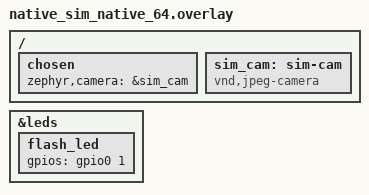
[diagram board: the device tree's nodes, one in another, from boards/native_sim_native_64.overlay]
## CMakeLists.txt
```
# SPDX-License-Identifier: Apache-2.0

cmake_minimum_required(VERSION 3.20.0)

# WiFi, PSRAM, coredump and hawkBit: every ESP32 board, none of it on native_sim
if(NOT BOARD MATCHES "^native_sim")
  list(APPEND EXTRA_CONF_FILE ${CMAKE_CURRENT_LIST_DIR}/esp32.conf)
endif()

find_package(Zephyr REQUIRED HINTS $ENV{ZEPHYR_BASE})

project(prusa_cam)

include(${CMAKE_CURRENT_LIST_DIR}/../common/http_util/http_util.cmake)
include(${CMAKE_CURRENT_LIST_DIR}/../common/prusa_camera/prusa_camera.cmake)
include(${CMAKE_CURRENT_LIST_DIR}/../common/build_id/build_id.cmake)
include(${CMAKE_CURRENT_LIST_DIR}/../common/watchdog/watchdog.cmake)
include(${CMAKE_CURRENT_LIST_DIR}/../common/img_confirm/img_confirm.cmake)

target_sources(app PRIVATE
  src/main.c
  src/cfg.c
  src/cam.c
  src/connect.c
  src/stream.c
  src/web.c
)
target_sources_ifdef(CONFIG_WIFI app PRIVATE src/wifi.c)
target_sources_ifdef(CONFIG_PRUSA_CAM_ESPHOME app PRIVATE src/ha.c)
target_include_directories(app PRIVATE src)

set(gen_dir ${ZEPHYR_BINARY_DIR}/include/generated)
generate_inc_file_for_target(app src/index.html ${gen_dir}/index.html.gz.inc --gzip)

if(CONFIG_DT_HAS_VND_JPEG_CAMERA_ENABLED)
  target_sources(app PRIVATE sim/sim_cam.c)
  generate_inc_file_for_target(app sim/frame.jpg ${gen_dir}/sim_frame.jpg.inc)
endif()

zephyr_linker_sources(SECTIONS sections-rom.ld)
zephyr_linker_section(NAME http_resource_desc_prusa_http
  KVMA RAM_REGION GROUP RODATA_REGION
)
```

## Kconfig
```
# SPDX-License-Identifier: Apache-2.0

mainmenu "prusa_cam"

menu "prusa_cam"

config PRUSA_CAM_CONNECT_STACK_SIZE
	int "Uploader thread stack size"
	default 6144
	help
	  The TLS handshake runs on this stack.

config PRUSA_CAM_STREAM_STACK_SIZE
	int "MJPEG stream thread stack size"
	default 2048

config PRUSA_CAM_MANUFACTURER
	string "Camera manufacturer reported to Prusa Connect"
	default "DFRobot" if BOARD_DFROBOT_ESP32S3_AI_CAM
	default "AI-Thinker"

config PRUSA_CAM_MODEL
	string "Camera model reported to Prusa Connect"
	default "DFR1154" if BOARD_DFROBOT_ESP32S3_AI_CAM
	default "ESP32-CAM"

# native_sim binds host ports: below 1024 needs root, and protective_stop
# has 8080 when twister runs both at once.
config PRUSA_CAM_HTTP_PORT
	int "Config page and API port"
	default 8280 if BOARD_NATIVE_SIM
	default 80

config PRUSA_CAM_STREAM_PORT
	int "MJPEG stream port"
	default 8281 if BOARD_NATIVE_SIM
	default 81
	help
	  The config page links to port 81.

config PRUSA_CAM_ESPHOME
	bool "Home Assistant (ESPHome native API)"
	default y
	select ESPHOME_API
	select ESPHOME_API_NOISE
	help
	  Show the camera in Home Assistant as an ESPHome device: the
	  picture, upload status, uploads, WiFi signal, the flash LED setting
	  and an upload button. Noise encrypted; set the key with `prusa ha_key` or the
	  config page. Until a key is set every client is refused.

config ZVFS_OPEN_ADD_SIZE_PRUSA_CAM_ESPHOME
	int
	default 2 if PRUSA_CAM_ESPHOME
	default 0
	help
	  The API's listening socket and its one client.

endmenu

rsource "../common/prusa_camera/Kconfig"
rsource "../common/build_id/Kconfig"
rsource "../common/watchdog/Kconfig"
rsource "../common/img_confirm/Kconfig"

source "Kconfig.zephyr"
```

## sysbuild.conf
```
# MCUboot, so hawkBit has a slot to download into.
SB_CONFIG_BOOTLOADER_MCUBOOT=y
# Espressif sysbuild defaults to overwrite-only, which cannot revert a bad
# image; swap-using-move reverts a trial image that is never confirmed.
SB_CONFIG_MCUBOOT_MODE_SWAP_USING_MOVE=y
```

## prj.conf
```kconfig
CONFIG_LOG=y
CONFIG_SHELL=y
CONFIG_MAIN_STACK_SIZE=4096
# 4096 for the hawkBit autohandler, which runs its HTTP buffers on this stack.
CONFIG_SYSTEM_WORKQUEUE_STACK_SIZE=4096

# Config + WiFi credentials in ZMS on the storage partition
CONFIG_FLASH=y
CONFIG_FLASH_MAP=y
CONFIG_ZMS=y
CONFIG_SETTINGS=y
CONFIG_SETTINGS_ZMS=y
CONFIG_HWINFO=y

# Camera: JPEG frames (OV2640 over I2S0 camera mode on the ESP32-CAM)
CONFIG_VIDEO=y
CONFIG_VIDEO_BUFFER_POOL_NUM_MAX=2
CONFIG_VIDEO_BUFFER_POOL_ALIGN=4
CONFIG_LED=y

# Networking; the WiFi station is in the board configuration
CONFIG_NETWORKING=y
CONFIG_NET_IPV4=y
CONFIG_NET_IPV6=n
CONFIG_NET_SOCKETS=y
CONFIG_NET_HOSTNAME_ENABLE=y
CONFIG_NET_HOSTNAME="prusa-zcam"

# HTTPS to Prusa Connect (the camera service)
CONFIG_PRUSA_CAMERA=y
CONFIG_HTTP_CLIENT=y
CONFIG_NET_SOCKETS_SOCKOPT_TLS=y
CONFIG_TLS_CREDENTIALS=y
CONFIG_MBEDTLS=y
CONFIG_MBEDTLS_ENABLE_HEAP=y
CONFIG_MBEDTLS_HEAP_SIZE=60000
# Server records can be 16 KiB (no max_fragment_length guarantee); requests are small chunks.
CONFIG_MBEDTLS_SSL_IN_CONTENT_LEN=16384
CONFIG_MBEDTLS_SSL_OUT_CONTENT_LEN=4096
CONFIG_MBEDTLS_SSL_PROTO_TLS1_2=y
CONFIG_MBEDTLS_X509_CRT_PARSE_C=y
CONFIG_MBEDTLS_SSL_SERVER_NAME_INDICATION=y
CONFIG_MBEDTLS_SSL_EXTENDED_MASTER_SECRET=y
# Let's Encrypt chains are RSA (R1x) or ECDSA (E-series); accept both.
CONFIG_MBEDTLS_KEY_EXCHANGE_ECDHE_RSA_ENABLED=y
CONFIG_MBEDTLS_KEY_EXCHANGE_ECDHE_ECDSA_ENABLED=y
CONFIG_PSA_WANT_ALG_ECDH=y
CONFIG_PSA_WANT_ALG_ECDSA=y
CONFIG_PSA_WANT_ALG_RSA_PKCS1V15_SIGN=y
CONFIG_PSA_WANT_ALG_RSA_PSS=y
CONFIG_PSA_WANT_ALG_SHA_256=y
CONFIG_PSA_WANT_ALG_SHA_384=y
CONFIG_PSA_WANT_ALG_GCM=y
CONFIG_PSA_WANT_ALG_HMAC=y
CONFIG_PSA_WANT_ALG_TLS12_PRF=y
CONFIG_PSA_WANT_KEY_TYPE_AES=y
CONFIG_PSA_WANT_KEY_TYPE_ECC_PUBLIC_KEY=y
CONFIG_PSA_WANT_KEY_TYPE_ECC_KEY_PAIR_IMPORT=y
CONFIG_PSA_WANT_KEY_TYPE_ECC_KEY_PAIR_EXPORT=y
CONFIG_PSA_WANT_KEY_TYPE_ECC_KEY_PAIR_GENERATE=y
CONFIG_PSA_WANT_KEY_TYPE_RSA_PUBLIC_KEY=y
CONFIG_PSA_WANT_KEY_TYPE_RSA_KEY_PAIR_IMPORT=y
CONFIG_PSA_WANT_ECC_SECP_R1_256=y
CONFIG_PSA_WANT_ECC_SECP_R1_384=y

# Home Assistant (PRUSA_CAM_ESPHOME): one client is enough for Home Assistant.
CONFIG_ESPHOME_API_MAX_CLIENTS=1
CONFIG_ESPHOME_API_FRIENDLY_NAME="Prusa camera"

# Config page / API
CONFIG_HTTP_SERVER=y
CONFIG_HTTP_PARSER=y
CONFIG_HTTP_SERVER_MAX_CLIENTS=2
CONFIG_HTTP_SERVER_STACK_SIZE=3072
CONFIG_HTTP_SERVER_VERSION_2=n
CONFIG_HTTP_SERVER_CAPTURE_HEADERS=y
# "Basic " + base64("admin:" + 32-char password) = 58; the default 32 cuts it
CONFIG_HTTP_SERVER_MAX_HEADER_LEN=58
CONFIG_JSON_LIBRARY=y
CONFIG_BASE64=y

# Stall detection. Also the deadline img_confirm reverts a trial image with.
CONFIG_APP_WATCHDOG=y
```

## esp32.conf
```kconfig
# Frames in PSRAM
CONFIG_VIDEO_BUFFER_USE_SHARED_MULTI_HEAP=y
CONFIG_VIDEO_BUFFER_SMH_ATTRIBUTE=2
CONFIG_ESP_SPIRAM=y
# DRAM is the tight resource on the ESP32 (mbedTLS heap + DMA ring + WiFi):
# put the WiFi adapter heap and net buffers in PSRAM.
CONFIG_ESP_WIFI_HEAP_SPIRAM=y
CONFIG_ESP32_WIFI_NET_ALLOC_SPIRAM=y
# Two UXGA JPEG buffers (2 x 384 KB) plus the WiFi heap.
CONFIG_ESP_SPIRAM_HEAP_SIZE=2097152
CONFIG_LED_PWM=y

# WiFi station
CONFIG_WIFI=y
CONFIG_NET_L2_WIFI_MGMT=y
CONFIG_NET_L2_WIFI_SHELL=y
CONFIG_WIFI_CREDENTIALS=y
CONFIG_WIFI_CREDENTIALS_BACKEND_SETTINGS=y
CONFIG_WIFI_CREDENTIALS_SHELL=y
CONFIG_NET_DHCPV4=y
CONFIG_NET_TCP=y
CONFIG_NET_SHELL=y
CONFIG_DNS_RESOLVER=y
# <hostname>.local, plus an _http._tcp record for the config page
CONFIG_MDNS_RESPONDER=y
CONFIG_DNS_SD=y
# HTTP server (listen + 2 clients), stream (listen + 1), TLS upload, DNS, mDNS,
# Home Assistant API (listen + 1) plus closed connections still in TIME_WAIT:
# with 10, back-to-back requests got RST
CONFIG_NET_MAX_CONTEXTS=18
CONFIG_NET_MAX_CONN=18
# app_wifi starts DHCP itself, or sets the static address instead.
CONFIG_WIFI_STA_AUTO_DHCPV4=n

# The ESP32 linker script puts .mbedtls_heap in PSRAM (ext_ram.bss).
CONFIG_MBEDTLS_HEAP_CUSTOM_SECTION=y

# The task watchdog's hardware fallback is the TIMG watchdog (watchdog0).
CONFIG_TASK_WDT_HW_FALLBACK=y

# Coredump to the 4 KB `coredump` flash partition, read back over the shell with
# `coredump find`, `coredump print` and `coredump erase`. The partition cannot
# hold RAM, so keep the faulting thread's registers and top 2 KB of stack; the
# default limit is unbounded.
CONFIG_DEBUG_COREDUMP=y
CONFIG_DEBUG_COREDUMP_BACKEND_FLASH_PARTITION=y
CONFIG_DEBUG_COREDUMP_SHELL=y
CONFIG_DEBUG_COREDUMP_MEMORY_DUMP_MIN=y
CONFIG_DEBUG_COREDUMP_THREAD_STACK_TOP_LIMIT_FOR_CURRENT=2048

# hawkBit OTA into MCUboot slot1. Build with --sysbuild (sysbuild.conf).
#
# A new image boots on trial and is confirmed once it has an IPv4 address and
# a frame from the camera (applications/common/img_confirm); otherwise the task
# watchdog resets it and MCUboot reverts. The autohandler only runs on a
# confirmed image, which is why HAWKBIT_CONFIRM_IMG_ON_INIT is off.
#
# Server, port and DDI token are set at runtime (`hawkbit set addr|port|
# ddi_token`) and kept in settings; the server may be a host name.
CONFIG_REBOOT=y
CONFIG_STREAM_FLASH=y
CONFIG_IMG_MANAGER=y
CONFIG_IMG_ERASE_PROGRESSIVELY=y
CONFIG_HAWKBIT=y
CONFIG_HAWKBIT_CONFIRM_IMG_ON_INIT=n
CONFIG_HAWKBIT_SET_SETTINGS_RUNTIME=y
CONFIG_HAWKBIT_USE_DOMAIN_NAME=y
CONFIG_HAWKBIT_SHELL=y
CONFIG_HAWKBIT_DDI_TARGET_SECURITY=y
CONFIG_HAWKBIT_HWINFO_DEVICE_ID=y
CONFIG_SMF=y
CONFIG_SMF_ANCESTOR_SUPPORT=y
# Resume an interrupted download (HTTP Range); progress saved every 5 %.
CONFIG_HAWKBIT_SAVE_PROGRESS=y
CONFIG_HAWKBIT_SAVE_PROGRESS_INTERVAL=5
CONFIG_STREAM_FLASH_PROGRESS=y
```

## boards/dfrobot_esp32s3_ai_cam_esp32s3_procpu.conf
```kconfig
# The DVP DMA writes a frame straight into its buffer: a UXGA JPEG buffer
# (1600 x 1200 / 5 B) takes 96 descriptors of 4032 B.
CONFIG_DMA_ESP32_MAX_DESCRIPTOR_NUM=100
# The GDMA stalls writing to PSRAM at less than 64-byte alignment.
CONFIG_VIDEO_BUFFER_POOL_ALIGN=64
```

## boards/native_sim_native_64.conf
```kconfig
# Host-backed BSD sockets: the HTTP server, the MJPEG stream and the uploads
# use the host's loopback directly, with no TAP interface and no root.
CONFIG_NET_SOCKETS_OFFLOAD=y
CONFIG_NET_NATIVE_OFFLOADED_SOCKETS=y
CONFIG_NET_DRIVERS=y
CONFIG_NET_L2_ETHERNET=n
CONFIG_NET_NATIVE=n

# ZMS on flash_simulator, persisted to a host file.
CONFIG_FLASH_SIMULATOR=y
CONFIG_FLASH_SIMULATOR_DOUBLE_WRITES=y

CONFIG_GPIO=y
CONFIG_PSA_CRYPTO=y
CONFIG_NET_MGMT=y
CONFIG_NET_MGMT_EVENT=y
CONFIG_NET_IF_UNICAST_IPV4_ADDR_COUNT=4
CONFIG_UART_NATIVE_PTY_0_ON_STDINOUT=y
# Sockets come from the fd table; NET_MAX_CONTEXTS sizes it on hardware.
CONFIG_ZVFS_OPEN_MAX=18
```

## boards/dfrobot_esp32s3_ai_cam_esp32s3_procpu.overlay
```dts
/* cam.c drives the "flash" through this label: the IR LEDs on this board. */
/ {
	pwmleds {
		flash_led: ir_led {};
	};
};
```

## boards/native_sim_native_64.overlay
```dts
/*
 * Copyright (c) 2026 Richard Osterloh <richard.osterloh@gmail.com>
 * SPDX-License-Identifier: Apache-2.0
 *
 * A canned-JPEG camera (sim/sim_cam.c) and a GPIO flash LED, so the whole app
 * runs on the host.
 */

/ {
	chosen {
		zephyr,camera = &sim_cam;
	};

	sim_cam: sim-cam {
		compatible = "vnd,jpeg-camera";
	};
};

&leds {
	flash_led: flash_led {
		gpios = <&gpio0 1 GPIO_ACTIVE_HIGH>;
	};
};
```

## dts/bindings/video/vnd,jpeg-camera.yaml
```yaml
# Copyright (c) 2026 Richard Osterloh
# SPDX-License-Identifier: Apache-2.0

description: |
  Stand-in JPEG camera for native_sim builds of prusa_cam: every frame is the
  same small JPEG (sim/frame.jpg).

compatible: "vnd,jpeg-camera"

include: base.yaml
```

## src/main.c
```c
/*
 * Copyright (c) 2026 Richard Osterloh <richard.osterloh@gmail.com>
 * SPDX-License-Identifier: Apache-2.0
 *
 * Prusa Connect camera: periodic JPEG snapshots from an OV2640 or OV3660 uploaded to
 * Prusa Connect, configured from the shell or a small web page.
 */

#include <stdlib.h>
#include <string.h>

#include <zephyr/dfu/mcuboot.h>
#include <zephyr/kernel.h>
#include <zephyr/logging/log.h>
#include <zephyr/mgmt/hawkbit/autohandler.h>
#include <zephyr/mgmt/hawkbit/hawkbit.h>
#include <zephyr/net/net_mgmt.h>
#include <zephyr/net/net_event.h>
#include <zephyr/shell/shell.h>

#include "app_img_confirm.h"
#include "app_watchdog.h"
#include "app_wifi.h"
#include "cam.h"
#include "cfg.h"
#include "connect.h"
#include "ha.h"
#include "http_util.h"
#include "prusa_camera.h"

LOG_MODULE_REGISTER(main, LOG_LEVEL_INF);

int web_init(void);

void cfg_changed(void)
{
	struct cfg c;

	cfg_get(&c);
	cam_apply(&c);
	connect_kick();
}

#define IP4(a) (a) >> 24, ((a) >> 16) & 0xFF, ((a) >> 8) & 0xFF, (a) & 0xFF

/* "dhcp" or "0" clears; otherwise A.B.C.D. */
static bool parse_ip(const char *val, uint32_t *out)
{
	if (strcmp(val, "dhcp") == 0 || strcmp(val, "0") == 0) {
		*out = 0;
		return true;
	}
	return http_parse_ipv4(val, out) == 0;
}

static int cmd_show(const struct shell *sh, size_t argc, char **argv)
{
	struct cfg c;
	struct connect_status st;

	cfg_get(&c);
	connect_get_status(&st);
	shell_print(sh, "name:        %s", c.name);
	shell_print(sh, "token:       %s", c.token[0] ? "set" : "not set");
	shell_print(sh, "password:    %s", c.password[0] ? "set" : "not set");
	shell_print(sh, "fingerprint: %s", cfg_fingerprint());
	shell_print(sh, "interval:    %u s", c.interval_s);
	shell_print(sh, "resolution:  %s", cfg_resolutions[c.resolution].name);
	shell_print(sh, "quality:     %u", c.quality);
	shell_print(sh, "hflip/vflip: %d/%d, flash: %d", c.hflip, c.vflip, c.flash);
	shell_print(sh, "rotation:    %u", c.rotation * 90);
	shell_print(sh, "brightness/contrast/saturation: %d/%d/%d", c.brightness, c.contrast,
		    c.saturation);
	shell_print(sh, "auto exposure/wb/gain: %d/%d/%d", c.auto_exposure, c.auto_wb, c.auto_gain);
	if (c.ip == 0) {
		shell_print(sh, "address:     DHCP");
	} else {
		shell_print(sh,
			    "address:     %u.%u.%u.%u/%u.%u.%u.%u gw %u.%u.%u.%u dns %u.%u.%u.%u",
			    IP4(c.ip), IP4(c.netmask), IP4(c.gateway), IP4(c.dns));
	}
	shell_print(sh, "uploads:     %u, last result %d (%s)%s", st.uploads, st.last_result,
		    st.last_ms ? prusa_camera_describe(st.last_result) : "none yet",
		    st.stopped ? ", stopped until the config changes" : "");
	memset(&c, 0, sizeof(c));
	return 0;
}

static int cmd_set(const struct shell *sh, size_t argc, char **argv)
{
	const char *key = argv[1];
	const char *val = argv[2];
	struct cfg c;
	int ret;

	cfg_get(&c);
	if (strcmp(key, "name") == 0 && strlen(val) <= CFG_NAME_MAX) {
		strcpy(c.name, val);
	} else if (strcmp(key, "token") == 0 && strlen(val) <= CFG_TOKEN_MAX) {
		strcpy(c.token, val);
	} else if (strcmp(key, "password") == 0 && strlen(val) <= CFG_PASSWORD_MAX) {
		strcpy(c.password, val);
	} else if (strcmp(key, "interval") == 0) {
		c.interval_s = CLAMP(strtol(val, NULL, 10), 0, UINT16_MAX);
	} else if (strcmp(key, "resolution") == 0 && cfg_resolution_find(val) >= 0) {
		c.resolution = cfg_resolution_find(val);
	} else if (strcmp(key, "quality") == 0) {
		c.quality = CLAMP(strtol(val, NULL, 10), 0, UINT8_MAX);
	} else if (strcmp(key, "hflip") == 0) {
		c.hflip = strtol(val, NULL, 10) != 0;
	} else if (strcmp(key, "vflip") == 0) {
		c.vflip = strtol(val, NULL, 10) != 0;
	} else if (strcmp(key, "flash") == 0) {
		c.flash = strtol(val, NULL, 10) != 0;
	} else if (strcmp(key, "rotation") == 0 && strtol(val, NULL, 10) % 90 == 0) {
		c.rotation = CLAMP(strtol(val, NULL, 10) / 90, 0, UINT8_MAX);
	} else if (strcmp(key, "brightness") == 0) {
		c.brightness = CLAMP(strtol(val, NULL, 10), INT8_MIN, INT8_MAX);
	} else if (strcmp(key, "contrast") == 0) {
		c.contrast = CLAMP(strtol(val, NULL, 10), INT8_MIN, INT8_MAX);
	} else if (strcmp(key, "saturation") == 0) {
		c.saturation = CLAMP(strtol(val, NULL, 10), INT8_MIN, INT8_MAX);
	} else if (strcmp(key, "auto_exposure") == 0) {
		c.auto_exposure = strtol(val, NULL, 10) != 0;
	} else if (strcmp(key, "auto_wb") == 0) {
		c.auto_wb = strtol(val, NULL, 10) != 0;
	} else if (strcmp(key, "auto_gain") == 0) {
		c.auto_gain = strtol(val, NULL, 10) != 0;
	} else if ((strcmp(key, "ip") == 0 && parse_ip(val, &c.ip)) ||
		   (strcmp(key, "netmask") == 0 && parse_ip(val, &c.netmask)) ||
		   (strcmp(key, "gateway") == 0 && parse_ip(val, &c.gateway)) ||
		   (strcmp(key, "dns") == 0 && parse_ip(val, &c.dns))) {
		/* parsed in place */
	} else {
		shell_error(sh, "bad key or value");
		return -EINVAL;
	}

	ret = cfg_set(&c);
	memset(&c, 0, sizeof(c));
	if (ret < 0) {
		shell_error(sh, "rejected (%d)", ret);
	}
	return ret;
}

static int cmd_test(const struct shell *sh, size_t argc, char **argv)
{
	connect_test();
	shell_print(sh, "test queued; see `prusa show` in a few seconds");
	return 0;
}

static int cmd_snap(const struct shell *sh, size_t argc, char **argv)
{
	connect_kick();
	shell_print(sh, "upload queued");
	return 0;
}

static int cmd_ha_key(const struct shell *sh, size_t argc, char **argv)
{
	int ret = ha_set_key(argv[1]);

	if (ret < 0) {
		shell_error(sh, "expected base64 of 32 bytes, or save failed (%d)", ret);
	}
	return ret;
}

SHELL_STATIC_SUBCMD_SET_CREATE(
	prusa_cmds,
	SHELL_CMD_ARG(show, NULL, "Show configuration and upload status", cmd_show, 1, 0),
	SHELL_CMD_ARG(
		set, NULL,
		"Set <name|token|password|interval|resolution|quality|hflip|vflip|flash|\n"
		"     rotation|brightness|contrast|saturation|auto_exposure|auto_wb|auto_gain|\n"
		"     ip|netmask|gateway|dns> <value>\n"
		"token: 20 letters/digits; interval: 10 30 60 600\n"
		"resolution: QVGA VGA SVGA XGA SXGA UXGA; rotation: 0 90 180 270\n"
		"brightness/contrast/saturation: -2..2; auto_*: 0 or 1\n"
		"ip: A.B.C.D or dhcp; set netmask and gateway first; applies on reconnect",
		cmd_set, 3, 0),
	SHELL_CMD_ARG(test, NULL, "Check token and fingerprint with the service", cmd_test, 1, 0),
	SHELL_CMD_ARG(snap, NULL, "Upload a snapshot now", cmd_snap, 1, 0),
	SHELL_COND_CMD_ARG(CONFIG_PRUSA_CAM_ESPHOME, ha_key, NULL,
			   "Set the Home Assistant encryption key <base64 of 32 bytes>", cmd_ha_key,
			   2, 0),
	SHELL_SUBCMD_SET_END);
SHELL_CMD_REGISTER(prusa, &prusa_cmds, "Prusa Connect camera", NULL);

/* Only on a confirmed image: the autohandler reboots an unconfirmed one, which
 * would cut the img_confirm deadline short. A confirmed image starts it even
 * with a broken camera, so OTA can fix it.
 */
static void hawkbit_start_fn(struct k_work *work)
{
	static bool started;
	int ret;

	if (!IS_ENABLED(CONFIG_HAWKBIT) || started || !boot_is_img_confirmed()) {
		return;
	}
	ret = hawkbit_init();
	if (ret < 0) {
		LOG_ERR("hawkBit init failed (%d)", ret);
		return;
	}
	started = true;
	hawkbit_autohandler(true);
}

static K_WORK_DEFINE(hawkbit_start, hawkbit_start_fn);

static bool cam_ok;
static struct net_mgmt_event_callback ipv4_cb;

/* Healthy = a frame from the camera and an IPv4 address. */
static void ipv4_added(struct net_mgmt_event_callback *cb, uint64_t event, struct net_if *iface)
{
	if (cam_ok) {
		app_img_confirm();
	}
	k_work_submit(&hawkbit_start);
}

static bool cam_check(void)
{
	const uint8_t *jpeg;
	size_t len;

	if (cam_frame(&jpeg, &len) < 0) {
		return false;
	}
	cam_release();
	return true;
}

int main(void)
{
	int ret;

	app_watchdog_init();
	app_img_confirm_arm();

	ret = cfg_init();
	if (ret < 0) {
		LOG_ERR("Config init failed (%d)", ret);
		return ret;
	}
	LOG_INF("Fingerprint %s", cfg_fingerprint());

	ret = cam_init();
	if (ret < 0) {
		LOG_ERR("Camera init failed (%d)", ret); /* keep going: the shell still works */
	} else {
		cam_ok = cam_check();
	}
	if (!cam_ok) {
		LOG_ERR("No frame from the camera; a trial image will be reverted");
	}

	ret = connect_init();
	if (ret < 0) {
		LOG_ERR("Connect init failed (%d)", ret);
		return ret;
	}

	if (IS_ENABLED(CONFIG_PRUSA_CAM_ESPHOME)) {
		ha_start();
	}

	ret = web_init();
	if (ret < 0) {
		LOG_ERR("HTTP server failed (%d)", ret);
	}

	net_mgmt_init_event_callback(&ipv4_cb, ipv4_added, NET_EVENT_IPV4_ADDR_ADD);
	net_mgmt_add_event_callback(&ipv4_cb);
	k_work_submit(&hawkbit_start);

	return IS_ENABLED(CONFIG_WIFI) ? app_wifi_init() : 0;
}
```

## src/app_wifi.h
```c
/*
 * Copyright (c) 2026 Richard Osterloh <richard.osterloh@gmail.com>
 * SPDX-License-Identifier: Apache-2.0
 */

#ifndef PRUSA_CAM_APP_WIFI_H_
#define PRUSA_CAM_APP_WIFI_H_

int app_wifi_init(void);
void app_wifi_reconnect(void);

#endif /* PRUSA_CAM_APP_WIFI_H_ */
```

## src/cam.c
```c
/*
 * Copyright (c) 2026 Richard Osterloh <richard.osterloh@gmail.com>
 * SPDX-License-Identifier: Apache-2.0
 */

#include <errno.h>

#include <zephyr/device.h>
#include <zephyr/drivers/led.h>
#include <zephyr/drivers/video.h>
#include <zephyr/kernel.h>
#include <zephyr/logging/log.h>
#include <zephyr/video/video.h>

#include "cam.h"

LOG_MODULE_REGISTER(cam, LOG_LEVEL_INF);

#define NBUF          2
#define FRAME_TIMEOUT K_SECONDS(3)
/* Upstream caps the flash LED at 80 % to spare it. */
#define FLASH_PERCENT 80
#define FLASH_SETTLE  K_MSEC(150)

static const struct device *const video = DEVICE_DT_GET(DT_CHOSEN(zephyr_camera));
static const struct led_dt_spec flash_led = LED_DT_SPEC_GET(DT_NODELABEL(flash_led));

static struct video_buffer *bufs[NBUF];
static struct video_buffer *held;
static bool use_flash;
static K_MUTEX_DEFINE(cam_lock);

static int set_ctrl(uint32_t id, int32_t val)
{
	struct video_control ctrl = {.id = id, .val = val};
	int ret = video_set_ctrl(video, &ctrl);

	if (ret < 0 && ret != -ENOTSUP) {
		LOG_WRN("ctrl 0x%x=%d: %d", id, val, ret);
	}
	return ret;
}

static void requeue_all(void)
{
	struct video_buffer *vb;

	while (video_dequeue(video, &vb, K_NO_WAIT) == 0) {
		video_enqueue(video, vb);
	}
}

int cam_apply(const struct cfg *c)
{
	const struct cfg_resolution *r = &cfg_resolutions[c->resolution];
	struct video_format fmt = {
		.type = VIDEO_BUF_TYPE_OUTPUT,
		.pixelformat = VIDEO_PIX_FMT_JPEG,
		.width = r->width,
		.height = r->height,
	};
	struct video_buffer *vb;
	int ret;

	if (!device_is_ready(video)) {
		return -ENODEV;
	}

	k_mutex_lock(&cam_lock, K_FOREVER);

	/* Stopping flushes every buffer to the output queue; drain it so none is queued twice. */
	video_stream_stop(video, VIDEO_BUF_TYPE_OUTPUT);
	while (video_dequeue(video, &vb, K_NO_WAIT) == 0) {
	}

	ret = video_set_format(video, &fmt);
	if (ret < 0) {
		LOG_ERR("%s JPEG not supported (%d)", r->name, ret);
		goto out;
	}

	/* The DVP driver estimates 2 B/px for JPEG; 1/5 B/px holds a frame at the
	 * default quality, and drivers drop a larger one.
	 */
	fmt.size = MIN(fmt.size, (uint32_t)fmt.width * fmt.height / 5);

	for (int i = 0; i < NBUF; i++) {
		if (bufs[i] != NULL && bufs[i]->size < fmt.size) {
			video_buffer_release(bufs[i]);
			bufs[i] = NULL;
		}
		if (bufs[i] == NULL) {
			bufs[i] = video_buffer_aligned_alloc(
				fmt.size, CONFIG_VIDEO_BUFFER_POOL_ALIGN, K_NO_WAIT);
			if (bufs[i] == NULL) {
				LOG_ERR("No memory for a %u B frame", fmt.size);
				ret = -ENOMEM;
				goto out;
			}
		}
		bufs[i]->type = VIDEO_BUF_TYPE_OUTPUT;
		video_enqueue(video, bufs[i]);
	}

	set_ctrl(VIDEO_CID_JPEG_COMPRESSION_QUALITY, c->quality);
	set_ctrl(VIDEO_CID_HFLIP, c->hflip);
	set_ctrl(VIDEO_CID_VFLIP, c->vflip);
	set_ctrl(VIDEO_CID_BRIGHTNESS, c->brightness);
	set_ctrl(VIDEO_CID_CONTRAST, c->contrast);
	set_ctrl(VIDEO_CID_SATURATION, c->saturation);
	/* The OV2640 driver uses these CIDs as on/off switches for its auto loops. */
	set_ctrl(VIDEO_CID_EXPOSURE, c->auto_exposure);
	set_ctrl(VIDEO_CID_WHITE_BALANCE_TEMPERATURE, c->auto_wb);
	set_ctrl(VIDEO_CID_GAIN, c->auto_gain);
	/* Other sensors (OV3660) take the standard auto controls. */
	set_ctrl(VIDEO_CID_EXPOSURE_AUTO,
		 c->auto_exposure ? VIDEO_EXPOSURE_AUTO : VIDEO_EXPOSURE_MANUAL);
	set_ctrl(VIDEO_CID_AUTO_WHITE_BALANCE, c->auto_wb);
	set_ctrl(VIDEO_CID_AUTOGAIN, c->auto_gain);
	use_flash = c->flash;

	ret = video_stream_start(video, VIDEO_BUF_TYPE_OUTPUT);
	if (ret == 0) {
		LOG_INF("Streaming %s JPEG, %u B buffers", r->name, fmt.size);
	}
out:
	k_mutex_unlock(&cam_lock);
	return ret;
}

int cam_init(void)
{
	struct cfg c;

	if (!device_is_ready(video)) {
		LOG_ERR("%s not ready", video->name);
		return -ENODEV;
	}
	if (!led_is_ready_dt(&flash_led)) {
		return -ENODEV;
	}
	cfg_get(&c);
	return cam_apply(&c);
}

static int grab(const uint8_t **jpeg, size_t *len, bool flash)
{
	int ret;

	if (!device_is_ready(video)) {
		return -ENODEV;
	}

	k_mutex_lock(&cam_lock, K_FOREVER);

	if (flash) {
		led_set_brightness_dt(&flash_led, FLASH_PERCENT);
		k_sleep(FLASH_SETTLE);
	}

	/* Frames already queued are stale: hand them back and wait for a new one. */
	requeue_all();
	ret = video_dequeue(video, &held, FRAME_TIMEOUT);

	if (flash) {
		led_off_dt(&flash_led);
	}

	if (ret < 0) {
		LOG_WRN("No frame (%d)", ret);
		k_mutex_unlock(&cam_lock);
		return ret;
	}

	*jpeg = held->buffer;
	*len = held->bytesused;
	return 0;
}

int cam_snapshot(const uint8_t **jpeg, size_t *len)
{
	return grab(jpeg, len, use_flash);
}

int cam_frame(const uint8_t **jpeg, size_t *len)
{
	return grab(jpeg, len, false);
}

void cam_release(void)
{
	video_enqueue(video, held);
	held = NULL;
	k_mutex_unlock(&cam_lock);
}
```

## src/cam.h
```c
/*
 * Copyright (c) 2026 Richard Osterloh <richard.osterloh@gmail.com>
 * SPDX-License-Identifier: Apache-2.0
 */

#ifndef PRUSA_CAM_CAM_H_
#define PRUSA_CAM_CAM_H_

#include <stddef.h>
#include <stdint.h>

#include "cfg.h"

int cam_init(void);

/* Apply resolution, quality and flips; restarts the stream. */
int cam_apply(const struct cfg *c);

/*
 * Take a fresh JPEG. On success the frame stays valid, and the camera
 * locked, until cam_release().
 */
int cam_snapshot(const uint8_t **jpeg, size_t *len);
/* As cam_snapshot(), never with the flash LED: for the MJPEG stream. */
int cam_frame(const uint8_t **jpeg, size_t *len);
void cam_release(void);

#endif /* PRUSA_CAM_CAM_H_ */
```

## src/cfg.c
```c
/*
 * Copyright (c) 2026 Richard Osterloh <richard.osterloh@gmail.com>
 * SPDX-License-Identifier: Apache-2.0
 */

/* strnlen() */
#define _POSIX_C_SOURCE 200809L

#include <errno.h>
#include <string.h>
#include <strings.h>

#include <zephyr/drivers/hwinfo.h>
#include <zephyr/kernel.h>
#include <zephyr/logging/log.h>
#include <zephyr/settings/settings.h>
#include <zephyr/sys/util.h>

#include "cfg.h"
#include "prusa_camera.h"

LOG_MODULE_REGISTER(cfg, LOG_LEVEL_INF);

const struct cfg_resolution cfg_resolutions[] = {
	{"QVGA", 320, 240}, {"VGA", 640, 480},    {"SVGA", 800, 600},
	{"XGA", 1024, 768}, {"SXGA", 1280, 1024}, {"UXGA", 1600, 1200},
};
const uint8_t cfg_resolution_count = ARRAY_SIZE(cfg_resolutions);

static struct cfg cfg = {
	.name = CONFIG_NET_HOSTNAME,
	.interval_s = 30,
	.resolution = 5, /* UXGA: the service suggests 1280x720..1920x1080 */
	.quality = 80,
	.auto_exposure = true,
	.auto_wb = true,
	.auto_gain = true,
};
static K_MUTEX_DEFINE(cfg_lock);
/* The service wants 16..64 characters; the MAC alone is 12 hex digits. */
#define FP_PREFIX "zephyrcam"
#define FP_ID_MAX ((40 - (sizeof(FP_PREFIX) - 1)) / 2)
static char fingerprint[sizeof(FP_PREFIX) + 2 * FP_ID_MAX];

static int cfg_load(const char *key, size_t len, settings_read_cb read_cb, void *cb_arg)
{
	struct cfg tmp = {0};
	ssize_t n;

	if (strcmp(key, "v1") != 0) {
		return 0;
	}
	n = read_cb(cb_arg, &tmp, sizeof(tmp));
	if (n != sizeof(tmp)) {
		LOG_WRN("Stored config has the wrong size, using defaults");
		return 0;
	}
	tmp.token[CFG_TOKEN_MAX] = '\0';
	tmp.password[CFG_PASSWORD_MAX] = '\0';
	tmp.name[CFG_NAME_MAX] = '\0';
	cfg = tmp;
	return 0;
}

SETTINGS_STATIC_HANDLER_DEFINE(prusa, "prusa", NULL, cfg_load, NULL, NULL);

int cfg_init(void)
{
	uint8_t id[FP_ID_MAX];
	ssize_t n = hwinfo_get_device_id(id, sizeof(id));
	int ret;

	if (n <= 0) {
		LOG_ERR("No device id (%d)", (int)n);
		return n < 0 ? (int)n : -EIO;
	}
	strcpy(fingerprint, FP_PREFIX);
	bin2hex(id, n, fingerprint + strlen(FP_PREFIX), sizeof(fingerprint) - strlen(FP_PREFIX));

	ret = settings_subsys_init();
	if (ret < 0) {
		return ret;
	}
	return settings_load_subtree("prusa");
}

void cfg_get(struct cfg *out)
{
	k_mutex_lock(&cfg_lock, K_FOREVER);
	*out = cfg;
	k_mutex_unlock(&cfg_lock);
}

int cfg_set(const struct cfg *in)
{
	struct cfg tmp = *in;
	int ret;

	if (prusa_camera_trigger_from_seconds(tmp.interval_s) < 0 ||
	    (tmp.token[0] != '\0' && !prusa_camera_token_valid(tmp.token)) || tmp.name[0] == '\0' ||
	    strnlen(tmp.name, sizeof(tmp.name)) > CFG_NAME_MAX ||
	    !IN_RANGE(tmp.brightness, -2, 2) || !IN_RANGE(tmp.contrast, -2, 2) ||
	    !IN_RANGE(tmp.saturation, -2, 2) || tmp.resolution >= cfg_resolution_count ||
	    tmp.quality > 100 || tmp.rotation > 3 ||
	    (tmp.ip != 0 && (tmp.netmask == 0 || tmp.gateway == 0)) ||
	    strnlen(tmp.token, sizeof(tmp.token)) > CFG_TOKEN_MAX ||
	    strnlen(tmp.password, sizeof(tmp.password)) > CFG_PASSWORD_MAX) {
		return -EINVAL;
	}

	k_mutex_lock(&cfg_lock, K_FOREVER);
	ret = settings_save_one("prusa/v1", &tmp, sizeof(tmp));
	if (ret == 0) {
		cfg = tmp;
	}
	k_mutex_unlock(&cfg_lock);

	if (ret == 0) {
		cfg_changed();
	}
	return ret;
}

int cfg_resolution_find(const char *name)
{
	for (int i = 0; i < cfg_resolution_count; i++) {
		if (strcasecmp(name, cfg_resolutions[i].name) == 0) {
			return i;
		}
	}
	return -1;
}

const char *cfg_fingerprint(void)
{
	return fingerprint;
}
```

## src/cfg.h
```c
/*
 * Copyright (c) 2026 Richard Osterloh <richard.osterloh@gmail.com>
 * SPDX-License-Identifier: Apache-2.0
 */

#ifndef PRUSA_CAM_CFG_H_
#define PRUSA_CAM_CFG_H_

#include <stdbool.h>
#include <stdint.h>

#define CFG_TOKEN_MAX    64
#define CFG_PASSWORD_MAX 32
#define CFG_NAME_MAX     32 /* Prusa Connect's limit */

struct cfg_resolution {
	const char *name;
	uint16_t width;
	uint16_t height;
};

struct cfg {
	char token[CFG_TOKEN_MAX + 1];
	char password[CFG_PASSWORD_MAX + 1];
	char name[CFG_NAME_MAX + 1]; /* shown in Prusa Connect */
	uint16_t interval_s;         /* 10, 30, 60 or 600: the service's trigger schemes */
	uint8_t resolution;          /* index into cfg_resolutions[] */
	uint8_t quality;             /* VIDEO_CID_JPEG_COMPRESSION_QUALITY */
	bool hflip;
	bool vflip;
	bool flash;
	uint8_t rotation; /* clockwise, 0..3 = 0/90/180/270 deg, for Connect and Exif */
	/* Host-order IPv4; ip == 0 means DHCP. Applied on the next WiFi connect. */
	uint32_t ip;
	uint32_t netmask;
	uint32_t gateway;
	uint32_t dns; /* 0: use the gateway */
	/* Sensor tuning: levels -2..2, the auto loops on or off */
	int8_t brightness;
	int8_t contrast;
	int8_t saturation;
	bool auto_exposure;
	bool auto_wb;
	bool auto_gain;
};

extern const struct cfg_resolution cfg_resolutions[];
extern const uint8_t cfg_resolution_count;

/* Load from settings (defaults for anything unset). */
int cfg_init(void);

/* Snapshot of the current configuration. */
void cfg_get(struct cfg *out);

/* Validate and persist; -EINVAL leaves the stored config untouched. */
int cfg_set(const struct cfg *in);

/* Index of a resolution by name, or -1. */
int cfg_resolution_find(const char *name);

/* Stable per-device id that Prusa Connect keys the camera on. */
const char *cfg_fingerprint(void);

/* Called after cfg_set() changes anything. */
void cfg_changed(void);

#endif /* PRUSA_CAM_CFG_H_ */
```

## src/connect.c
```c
/*
 * Copyright (c) 2026 Richard Osterloh <richard.osterloh@gmail.com>
 * SPDX-License-Identifier: Apache-2.0
 *
 * Prusa camera service API v1 (https://camera-service.prusa3d.com/docs/):
 * PUT /v1/camera-info (JSON) once and after each config change, then
 * PUT /v1/snapshot (JPEG, at most 1 MB and 6 a minute), each with Token,
 * Fingerprint and User-Agent headers, over HTTPS.
 */

#include <string.h>

#include <zephyr/kernel.h>
#include <zephyr/logging/log.h>
#include <zephyr/net/net_if.h>
#include <zephyr/net/net_mgmt.h>
#include <zephyr/net/wifi_mgmt.h>
#include <zephyr/sys/atomic.h>

#include <zephyr/app_version.h>

#include "cam.h"
#include "cfg.h"
#include "connect.h"
#include "prusa_camera.h"

LOG_MODULE_REGISTER(connect, LOG_LEVEL_INF);

#define BACKOFF_MAX_S 600

enum {
	INFO_STALE,
	TEST_REQUESTED
};

static K_SEM_DEFINE(kick, 0, 1);
static K_MUTEX_DEFINE(status_lock);
static struct connect_status status;
static atomic_t flags = ATOMIC_INIT(BIT(INFO_STALE));
static struct net_mgmt_event_callback addr_cb;

/* network_info for camera-info, filled from the WiFi station interface. */
static struct {
	char mac[sizeof("00:00:00:00:00:00")];
	char ipv4[NET_IPV4_ADDR_LEN];
	char ssid[WIFI_SSID_MAX_LEN + 1];
} net;

static void net_info_update(void)
{
	struct net_if *iface = net_if_get_wifi_sta();
	struct wifi_iface_status st = {0};
	struct net_linkaddr *ll;
	struct net_in_addr *a;

	memset(&net, 0, sizeof(net));
	if (!IS_ENABLED(CONFIG_WIFI) || iface == NULL) {
		return;
	}
	ll = net_if_get_link_addr(iface);
	if (ll != NULL && ll->len == 6) {
		snprintk(net.mac, sizeof(net.mac), "%02x:%02x:%02x:%02x:%02x:%02x", ll->addr[0],
			 ll->addr[1], ll->addr[2], ll->addr[3], ll->addr[4], ll->addr[5]);
	}
	a = net_if_ipv4_get_global_addr(iface, NET_ADDR_PREFERRED);
	if (a != NULL) {
		net_addr_ntop(NET_AF_INET, a, net.ipv4, sizeof(net.ipv4));
	}
	if (net_mgmt(NET_REQUEST_WIFI_IFACE_STATUS, iface, &st, sizeof(st)) == 0 &&
	    st.state >= WIFI_STATE_ASSOCIATED) {
		memcpy(net.ssid, st.ssid, MIN(st.ssid_len, WIFI_SSID_MAX_LEN));
	}
}

/*
 * A new address goes into camera-info, so Connect shows where the camera is.
 * Try now too: after an outage the backoff may have grown to 10 minutes.
 */
static void addr_event(struct net_mgmt_event_callback *cb, uint64_t event, struct net_if *iface)
{
	atomic_set_bit(&flags, INFO_STALE);
	k_sem_give(&kick);
}

static int send_info(const struct prusa_camera_auth *auth, const struct cfg *c)
{
	net_info_update();

	const struct prusa_camera_info info = {
		.name = c->name,
		.trigger = prusa_camera_trigger_from_seconds(c->interval_s),
		.rotation = c->rotation * 90,
		.width = cfg_resolutions[c->resolution].width,
		.height = cfg_resolutions[c->resolution].height,
		.wifi_mac = net.mac,
		.wifi_ipv4 = net.ipv4,
		.wifi_ssid = net.ssid,
		.type = "ESP32",
		.firmware_version = APP_VERSION_STRING,
		.hardware_version = CONFIG_PRUSA_CAM_MANUFACTURER " " CONFIG_PRUSA_CAM_MODEL,
		.manufacturer = CONFIG_PRUSA_CAM_MANUFACTURER,
		.model = CONFIG_PRUSA_CAM_MODEL,
	};

	return prusa_camera_put_info(auth, &info);
}

static int send_snapshot(const struct prusa_camera_auth *auth)
{
	const uint8_t *jpeg;
	size_t len;
	int ret = cam_snapshot(&jpeg, &len);

	if (ret < 0) {
		return ret;
	}
	ret = prusa_camera_put_snapshot(auth, jpeg, len);
	cam_release();
	LOG_INF("Snapshot %u B -> %d", len, ret);
	return ret;
}

static void record(int result, bool uploaded, bool stopped)
{
	k_mutex_lock(&status_lock, K_FOREVER);
	status.last_ms = k_uptime_get();
	status.last_result = result;
	status.uploads += uploaded;
	status.stopped = stopped;
	k_mutex_unlock(&status_lock);
}

/*
 * One step of the upload loop: a requested connection test, camera-info when
 * it is stale, else a snapshot. Returns what the service said to do next.
 */
static enum prusa_camera_next step(const struct prusa_camera_auth *auth, const struct cfg *c,
				   bool *stopped)
{
	static const char *const what[] = {"test", "camera-info", "snapshot"};
	enum {
		TEST,
		INFO,
		SNAPSHOT
	} kind;
	enum prusa_camera_next next;
	int ret;

	if (atomic_test_and_clear_bit(&flags, TEST_REQUESTED)) {
		kind = TEST;
		ret = prusa_camera_get_info(auth);
	} else if (*stopped) {
		return PRUSA_CAMERA_NEXT_STOP;
	} else if (atomic_test_bit(&flags, INFO_STALE)) {
		kind = INFO;
		ret = send_info(auth, c);
	} else {
		kind = SNAPSHOT;
		ret = send_snapshot(auth);
	}

	next = prusa_camera_next(ret);
	if (kind == INFO && next == PRUSA_CAMERA_NEXT_OK) {
		atomic_clear_bit(&flags, INFO_STALE);
	}
	/* A passing test clears a stop: the token may have been fixed in Connect. */
	*stopped = next == PRUSA_CAMERA_NEXT_STOP;
	if (next != PRUSA_CAMERA_NEXT_OK) {
		LOG_WRN("%s -> %d: %s", what[kind], ret, prusa_camera_describe(ret));
	} else if (kind == TEST) {
		LOG_INF("Connection test passed");
	}
	record(ret, kind == SNAPSHOT && next == PRUSA_CAMERA_NEXT_OK, *stopped);
	return next;
}

static void connect_thread(void *p1, void *p2, void *p3)
{
	struct cfg c;
	struct prusa_camera_auth auth = {.token = c.token, .fingerprint = cfg_fingerprint()};
	uint32_t fails = 0;
	bool stopped = false;

	while (true) {
		uint32_t wait;

		cfg_get(&c);
		/* Back off on network or server trouble, doubling up to 10 minutes. */
		wait = MIN((uint32_t)c.interval_s << MIN(fails, 6), BACKOFF_MAX_S);
		wait = MAX(wait, c.interval_s);
		if (k_sem_take(&kick, K_SECONDS(wait)) == 0) {
			stopped = atomic_test_bit(&flags, TEST_REQUESTED) ? stopped : false;
		}

		cfg_get(&c);
		if (c.token[0] == '\0') {
			continue;
		}

		switch (step(&auth, &c, &stopped)) {
		case PRUSA_CAMERA_NEXT_RETRY:
			fails++;
			break;
		case PRUSA_CAMERA_NEXT_OK:
			fails = 0;
			break;
		default: /* WAIT: keep the cadence; STOP: wait for a config change */
			break;
		}
	}
}

K_THREAD_DEFINE(connect_tid, CONFIG_PRUSA_CAM_CONNECT_STACK_SIZE, connect_thread, NULL, NULL, NULL,
		K_LOWEST_APPLICATION_THREAD_PRIO, 0, SYS_FOREVER_MS);

int connect_init(void)
{
	int ret = prusa_camera_init("prusa_cam/" APP_VERSION_STRING);

	if (ret < 0) {
		return ret;
	}
	net_mgmt_init_event_callback(&addr_cb, addr_event, NET_EVENT_IPV4_ADDR_ADD);
	net_mgmt_add_event_callback(&addr_cb);
	k_thread_start(connect_tid);
	return 0;
}

void connect_kick(void)
{
	atomic_set_bit(&flags, INFO_STALE);
	k_sem_give(&kick);
}

void connect_test(void)
{
	atomic_set_bit(&flags, TEST_REQUESTED);
	k_sem_give(&kick);
}

void connect_get_status(struct connect_status *out)
{
	k_mutex_lock(&status_lock, K_FOREVER);
	*out = status;
	k_mutex_unlock(&status_lock);
}
```

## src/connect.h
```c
/*
 * Copyright (c) 2026 Richard Osterloh <richard.osterloh@gmail.com>
 * SPDX-License-Identifier: Apache-2.0
 */

#ifndef PRUSA_CAM_CONNECT_H_
#define PRUSA_CAM_CONNECT_H_

#include <stdint.h>

struct connect_status {
	int64_t last_ms;  /* uptime of the last attempt, 0 = none */
	int last_result;  /* HTTP status, or -errno */
	uint32_t uploads; /* successful snapshot uploads */
	bool stopped;     /* refused by the service; waits for a config change */
};

int connect_init(void);

/* Upload a snapshot now (and resend camera info) instead of waiting. */
void connect_kick(void);

/* Check the token and fingerprint with GET /v1/camera-info; see last_result. */
void connect_test(void);

void connect_get_status(struct connect_status *out);

#endif /* PRUSA_CAM_CONNECT_H_ */
```

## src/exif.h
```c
/*
 * Copyright (c) 2026 Richard Osterloh <richard.osterloh@gmail.com>
 * SPDX-License-Identifier: Apache-2.0
 *
 * A minimal Exif APP1 segment carrying only the Orientation tag, so viewers
 * (Prusa Connect, browsers) show a rotated camera upright without the
 * firmware re-encoding the JPEG. Header-only so it can be tested on
 * native_sim.
 */

#ifndef PRUSA_CAM_EXIF_H_
#define PRUSA_CAM_EXIF_H_

#include <stdbool.h>
#include <stddef.h>
#include <stdint.h>
#include <string.h>

/* SOI followed by the APP1 segment; replaces the frame's own SOI. */
#define EXIF_HDR_LEN 38

/* Exif Orientation for a clockwise rotation index 0..3 (0/90/180/270 deg). */
static inline uint16_t exif_orientation(uint8_t rotation)
{
	static const uint16_t orient[] = {1, 6, 3, 8};

	return rotation < 4 ? orient[rotation] : 1;
}

static inline void exif_header(uint8_t out[EXIF_HDR_LEN], uint16_t orientation)
{
	static const uint8_t tmpl[EXIF_HDR_LEN] = {
		0xFF, 0xD8,                                     /* SOI */
		0xFF, 0xE1, 0x00, 0x22,                         /* APP1, 34 bytes */
		'E',  'x',  'i',  'f',  0x00, 0x00,             /* Exif identifier */
		'M',  'M',  0x00, 0x2A, 0x00, 0x00, 0x00, 0x08, /* big-endian TIFF, IFD0 at 8 */
		0x00, 0x01,                                     /* one IFD0 entry */
		0x01, 0x12, 0x00, 0x03, 0x00, 0x00, 0x00, 0x01, /* Orientation, SHORT, count 1 */
		0x00, 0x00, 0x00, 0x00,                         /* value, patched below */
		0x00, 0x00, 0x00, 0x00,                         /* no IFD1 */
	};

	memcpy(out, tmpl, sizeof(tmpl));
	out[30] = orientation >> 8;
	out[31] = orientation & 0xFF;
}

/*
 * Whether to send exif_header() + jpeg[2..] instead of jpeg: only for a
 * rotated image, and only if the frame starts with SOI.
 */
static inline bool exif_wanted(const uint8_t *jpeg, size_t len, uint8_t rotation)
{
	return rotation != 0 && rotation < 4 && len >= 2 && jpeg[0] == 0xFF && jpeg[1] == 0xD8;
}

#endif /* PRUSA_CAM_EXIF_H_ */
```

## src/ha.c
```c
/*
 * Copyright (c) 2026 Richard Osterloh <richard.osterloh@gmail.com>
 * SPDX-License-Identifier: Apache-2.0
 *
 * Home Assistant over the ESPHome native API: the camera, upload status, WiFi
 * signal, the flash setting and a snapshot-now button. A low-priority thread polls the
 * uploader and config and publishes changes.
 */

#include <errno.h>
#include <string.h>

#include <zephyr/kernel.h>
#include <zephyr/logging/log.h>
#include <zephyr/net/esphome_api.h>
#include <zephyr/net/net_if.h>
#include <zephyr/net/wifi_mgmt.h>
#include <zephyr/settings/settings.h>
#include <zephyr/sys/base64.h>

#include "cam.h"
#include "cfg.h"
#include "connect.h"
#include "ha.h"

LOG_MODULE_REGISTER(ha, LOG_LEVEL_INF);

#define POLL_MS    1000
#define RSSI_POLLS 30

static void flash_set(struct esphome_entity *e, bool on)
{
	struct cfg c;

	cfg_get(&c);
	c.flash = on;
	if (cfg_set(&c) < 0) {
		on = !on;
	}
	memset(&c, 0, sizeof(c));
	(void)esphome_api_publish_bool(e, on);
}

static void snapshot_press(struct esphome_entity *e)
{
	ARG_UNUSED(e);
	connect_kick();
}

/* As the MJPEG stream: no flash, and the camera stays locked while the frame is sent. */
static int image_get(struct esphome_entity *e, const uint8_t **data, size_t *len)
{
	ARG_UNUSED(e);
	return cam_frame(data, len);
}

static void image_release(struct esphome_entity *e)
{
	ARG_UNUSED(e);
	cam_release();
}

ESPHOME_CAMERA_DEFINE(camera, .name = "Camera", .get_image = image_get,
		      .release_image = image_release);
ESPHOME_BINARY_SENSOR_DEFINE(upload_problem, .name = "Upload", .device_class = "problem");
ESPHOME_SENSOR_DEFINE(uploads, .name = "Uploads", .icon = "mdi:cloud-upload",
		      .state_class = ESPHOME_STATE_CLASS_TOTAL_INCREASING,
		      .entity_category = ESPHOME_ENTITY_CATEGORY_DIAGNOSTIC);
ESPHOME_SENSOR_DEFINE(wifi_signal, .name = "WiFi signal", .unit = "dBm",
		      .device_class = "signal_strength",
		      .state_class = ESPHOME_STATE_CLASS_MEASUREMENT,
		      .entity_category = ESPHOME_ENTITY_CATEGORY_DIAGNOSTIC);
ESPHOME_SWITCH_DEFINE(flash, .name = "Flash LED", .icon = "mdi:flash",
		      .entity_category = ESPHOME_ENTITY_CATEGORY_CONFIG, .on_switch = flash_set);
ESPHOME_BUTTON_DEFINE(snapshot, .name = "Upload snapshot", .icon = "mdi:camera",
		      .on_press = snapshot_press);

int ha_set_key(const char *b64)
{
	uint8_t key[32];
	size_t len = 0U;
	int ret;

	if (base64_decode(key, sizeof(key), &len, (const uint8_t *)b64, strlen(b64)) != 0 ||
	    len != sizeof(key)) {
		return -EINVAL;
	}
	ret = esphome_api_set_psk(key);
	memset(key, 0, sizeof(key));
	return ret;
}

static int rssi_get(void)
{
	struct net_if *iface = net_if_get_wifi_sta();
	struct wifi_iface_status st = {0};

	if (!IS_ENABLED(CONFIG_WIFI) || iface == NULL ||
	    net_mgmt(NET_REQUEST_WIFI_IFACE_STATUS, iface, &st, sizeof(st)) != 0 ||
	    st.state < WIFI_STATE_ASSOCIATED) {
		return 0;
	}
	return st.rssi;
}

static void ha_thread(void *p1, void *p2, void *p3)
{
	int last_problem = -1;
	uint32_t last_uploads = UINT32_MAX;
	int last_flash = -1;
	int last_rssi = 1;

	ARG_UNUSED(p1);
	ARG_UNUSED(p2);
	ARG_UNUSED(p3);

	/* cfg_init() loads only "prusa"; the API key lives here. */
	(void)settings_load_subtree("esphome_api");

	for (uint32_t n = 0U;; n++) {
		struct connect_status st;
		struct cfg c;

		connect_get_status(&st);
		cfg_get(&c);

		/* Unknown in Home Assistant until the first attempt. */
		if (st.last_ms != 0) {
			int problem = st.stopped || st.last_result < 200 || st.last_result >= 300;

			if (problem != last_problem) {
				(void)esphome_api_publish_bool(&upload_problem, problem);
				last_problem = problem;
			}
		}
		if (st.uploads != last_uploads) {
			(void)esphome_api_publish_float(&uploads, (float)st.uploads);
			last_uploads = st.uploads;
		}
		if (c.flash != last_flash) {
			(void)esphome_api_publish_bool(&flash, c.flash);
			last_flash = c.flash;
		}
		if (IS_ENABLED(CONFIG_WIFI) && n % RSSI_POLLS == 0U) {
			int rssi = rssi_get();

			if (rssi != 0 && rssi != last_rssi) {
				(void)esphome_api_publish_float(&wifi_signal, (float)rssi);
				last_rssi = rssi;
			}
		}
		memset(&c, 0, sizeof(c)); /* holds the token and password */

		k_sleep(K_MSEC(POLL_MS));
	}
}

K_THREAD_DEFINE(prusa_ha, 1536, ha_thread, NULL, NULL, NULL, K_LOWEST_APPLICATION_THREAD_PRIO, 0,
		SYS_FOREVER_MS);

void ha_start(void)
{
	k_thread_start(prusa_ha);
}
```

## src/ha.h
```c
/*
 * Copyright (c) 2026 Richard Osterloh <richard.osterloh@gmail.com>
 * SPDX-License-Identifier: Apache-2.0
 */

#ifndef PRUSA_CAM_HA_H_
#define PRUSA_CAM_HA_H_

/* Set the Home Assistant API encryption key from its base64 form (32 bytes) and
 * save it. -EINVAL for a malformed key, else esphome_api_set_psk()'s result.
 */
int ha_set_key(const char *b64);

/* Start publishing; after cfg_init() and connect_init(). */
void ha_start(void);

#endif /* PRUSA_CAM_HA_H_ */
```

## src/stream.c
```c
/*
 * Copyright (c) 2026 Richard Osterloh <richard.osterloh@gmail.com>
 * SPDX-License-Identifier: Apache-2.0
 *
 * MJPEG stream (multipart/x-mixed-replace) on its own port, one viewer at a
 * time. It has its own socket and thread because the HTTP server runs every
 * dynamic response to completion on its one thread: a stream there would
 * block the config page for as long as anyone watched.
 */

#include <errno.h>
#include <stdio.h>
#include <string.h>
#include <strings.h>

#include <zephyr/kernel.h>
#include <zephyr/logging/log.h>
#include <zephyr/net/socket.h>

#include "cam.h"
#include "cfg.h"
#include "http_util.h"

LOG_MODULE_REGISTER(stream, LOG_LEVEL_INF);

#define PORT        CONFIG_PRUSA_CAM_STREAM_PORT
#define IO_TIMEOUT  5 /* seconds; also bounds a viewer that stops reading */
#define AUTH_PREFIX "Authorization:"

static char req[768];

static int send_all(int sock, const void *buf, size_t len)
{
	const uint8_t *p = buf;

	while (len > 0) {
		ssize_t n = zsock_send(sock, p, len, 0);

		if (n < 0) {
			return -errno;
		}
		p += n;
		len -= n;
	}
	return 0;
}

static int send_str(int sock, const char *s)
{
	return send_all(sock, s, strlen(s));
}

/* Read the request head; 0 once "\r\n\r\n" is in req (NUL-terminated). */
static int read_head(int sock)
{
	size_t len = 0;

	while (len < sizeof(req) - 1) {
		ssize_t n = zsock_recv(sock, &req[len], sizeof(req) - 1 - len, 0);

		if (n <= 0) {
			return -EIO;
		}
		len += n;
		req[len] = '\0';
		char *end = strstr(req, "\r\n\r\n");

		if (end != NULL) {
			end[2] = '\0'; /* every header line, the last too, now ends in \r\n */
			return 0;
		}
	}
	return -E2BIG;
}

/* The Authorization header value, NUL-terminated in place, or "". */
static const char *auth_header(void)
{
	for (char *line = strstr(req, "\r\n"); line != NULL; line = strstr(line, "\r\n")) {
		line += 2;
		if (strncasecmp(line, AUTH_PREFIX, strlen(AUTH_PREFIX)) == 0) {
			char *v = line + strlen(AUTH_PREFIX);
			char *end = strstr(v, "\r\n");

			while (*v == ' ') {
				v++;
			}
			*end = '\0'; /* read_head() left a \r\n after every line */
			return v;
		}
	}
	return "";
}

/* Check method, path and credentials; on failure the error is sent. */
static bool request_ok(int sock)
{
	struct cfg c;
	bool ok;

	if (strncmp(req, "GET / ", 6) != 0 && strncmp(req, "GET /stream ", 12) != 0) {
		send_str(sock, "HTTP/1.1 404 Not Found\r\nConnection: close\r\n\r\n");
		return false;
	}
	cfg_get(&c);
	if (c.password[0] == '\0') {
		memset(&c, 0, sizeof(c));
		send_str(sock, "HTTP/1.1 403 Forbidden\r\nConnection: close\r\n\r\n"
			       "set a password: prusa set password\n");
		return false;
	}
	ok = http_basic_auth_ok(auth_header(), "admin", c.password);
	memset(&c, 0, sizeof(c));
	if (!ok) {
		send_str(sock, "HTTP/1.1 401 Unauthorized\r\n"
			       "WWW-Authenticate: Basic realm=\"prusa_cam\"\r\n"
			       "Connection: close\r\n\r\n");
	}
	return ok;
}

static void serve(int sock)
{
	const struct zsock_timeval tv = {.tv_sec = IO_TIMEOUT};
	char part[96];
	const uint8_t *jpeg;
	size_t len;
	int ret = 0;

	zsock_setsockopt(sock, SOL_SOCKET, SO_RCVTIMEO, &tv, sizeof(tv));
	zsock_setsockopt(sock, SOL_SOCKET, SO_SNDTIMEO, &tv, sizeof(tv));

	if (read_head(sock) < 0 || !request_ok(sock)) {
		return;
	}
	memset(req, 0, sizeof(req)); /* drop the credentials */

	if (send_str(sock, "HTTP/1.1 200 OK\r\n"
			   "Content-Type: multipart/x-mixed-replace; boundary=frame\r\n"
			   "Cache-Control: no-store\r\nConnection: close\r\n\r\n") < 0) {
		return;
	}
	LOG_INF("Viewer connected");

	while (ret == 0) {
		if (cam_frame(&jpeg, &len) < 0) {
			k_sleep(K_SECONDS(1));
			continue;
		}
		snprintf(part, sizeof(part),
			 "--frame\r\nContent-Type: image/jpeg\r\nContent-Length: %u\r\n\r\n",
			 (unsigned int)len);
		ret = send_str(sock, part);
		if (ret == 0) {
			ret = send_all(sock, jpeg, len);
		}
		cam_release();
		if (ret == 0) {
			ret = send_str(sock, "\r\n");
		}
	}
	LOG_INF("Viewer gone (%d)", ret);
}

static void stream_thread(void *a, void *b, void *c)
{
	struct net_sockaddr_in addr = {
		.sin_family = NET_AF_INET,
		.sin_port = net_htons(PORT),
	};
	int one = 1;
	int srv = zsock_socket(NET_AF_INET, NET_SOCK_STREAM, NET_IPPROTO_TCP);

	if (srv < 0 || zsock_setsockopt(srv, SOL_SOCKET, SO_REUSEADDR, &one, sizeof(one)) < 0 ||
	    zsock_bind(srv, (struct net_sockaddr *)&addr, sizeof(addr)) < 0 ||
	    zsock_listen(srv, 1) < 0) {
		LOG_ERR("Stream port %d unavailable (%d)", PORT, -errno);
		return;
	}

	for (;;) {
		int sock = zsock_accept(srv, NULL, NULL);

		if (sock < 0) {
			k_sleep(K_SECONDS(1));
			continue;
		}
		serve(sock);
		zsock_close(sock);
	}
}

K_THREAD_DEFINE(stream_tid, CONFIG_PRUSA_CAM_STREAM_STACK_SIZE, stream_thread, NULL, NULL, NULL,
		K_LOWEST_APPLICATION_THREAD_PRIO, 0, 0);
```
